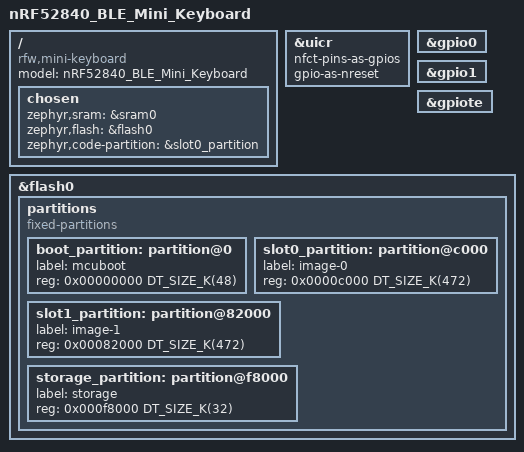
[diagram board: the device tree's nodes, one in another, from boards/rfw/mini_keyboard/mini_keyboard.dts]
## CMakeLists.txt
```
cmake_minimum_required(VERSION 3.20.0)
include_directories(inc)

find_package(Zephyr REQUIRED HINTS $ENV{ZEPHYR_BASE})

project(Keyboard)

target_sources(app PRIVATE src/main.c)
```

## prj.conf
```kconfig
CONFIG_ASSERT=y
CONFIG_HEAP_MEM_POOL_SIZE=4096

# Clock RC: Release P0.26 from XL1 crystal
CONFIG_CLOCK_CONTROL_NRF_K32SRC_RC=y
CONFIG_CLOCK_CONTROL_NRF_K32SRC_XTAL=n

# GPIO and interrupt support
CONFIG_GPIO=y

# CAF Framework & Event Manager
CONFIG_CAF=y
CONFIG_APP_EVENT_MANAGER=y
CONFIG_APP_EVENT_MANAGER_MAX_EVENT_CNT=256

# CAF Buttons module
CONFIG_CAF_BUTTONS=y
CONFIG_CAF_BUTTONS_DEF_PATH="buttons_def.h"
CONFIG_CAF_BUTTONS_POLARITY_INVERSED=n
CONFIG_CAF_BUTTONS_SCAN_INTERVAL=2
CONFIG_CAF_BUTTONS_DEBOUNCE_INTERVAL=5

# RTT Output for debugging
CONFIG_CONSOLE=y
CONFIG_USE_SEGGER_RTT=y
CONFIG_RTT_CONSOLE=y
CONFIG_LOG=y
CONFIG_LOG_BACKEND_RTT=y
```

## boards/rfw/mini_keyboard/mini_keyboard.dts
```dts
/dts-v1/;
#include <nordic/nrf52840_qiaa.dtsi>
#include "mini_keyboard-pinctrl.dtsi"

/ {
	model = "nRF52840_BLE_Mini_Keyboard";
	compatible = "rfw,mini-keyboard";

	chosen {
		zephyr,sram = &sram0;
		zephyr,flash = &flash0;
		zephyr,code-partition = &slot0_partition;
	};
};

&uicr {
	nfct-pins-as-gpios;
	gpio-as-nreset;
};

&gpio0 {
	status = "okay";
};

&gpio1 {
	status = "okay";
};

&gpiote {
	status = "okay";
};

&flash0 {
	partitions {
		compatible = "fixed-partitions";
		#address-cells = <1>;
		#size-cells = <1>;

		boot_partition: partition@0 {
			label = "mcuboot";
			reg = <0x00000000 DT_SIZE_K(48)>;
		};

		slot0_partition: partition@c000 {
			label = "image-0";
			reg = <0x0000c000 DT_SIZE_K(472)>;
		};

		slot1_partition: partition@82000 {
			label = "image-1";
			reg = <0x00082000 DT_SIZE_K(472)>;
		};

		storage_partition: partition@f8000 {
			label = "storage";
			reg = <0x000f8000 DT_SIZE_K(32)>;
		};
	};
};
```

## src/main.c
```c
/*
 * Copyright (c) 2026 rfw
 * SPDX-License-Identifier: Apache-2.0
 */

#include <zephyr/kernel.h>
#include <zephyr/sys/printk.h>
#include <app_event_manager.h>
#include <caf/events/button_event.h>
#include <caf/key_id.h>

#define MODULE main
#include <caf/events/module_state_event.h>

#include <zephyr/logging/log.h>
LOG_MODULE_REGISTER(MODULE);

static bool event_handler(const struct app_event_header *eh)
{
	if (is_button_event(eh)) {
		const struct button_event *event = cast_button_event(eh);

		if (event->pressed) {
			printk("[%d,%d]\n", KEY_ROW(event->key_id), KEY_COL(event->key_id));
		}
		return false;
	}
	return false;
}

APP_EVENT_LISTENER(main, event_handler);
APP_EVENT_SUBSCRIBE(main, button_event);

int main(void)
{
	if (app_event_manager_init()) {
		LOG_ERR("Application Event Manager init failed");
		return -1;
	}

	module_set_state(MODULE_STATE_READY);
	return 0;
}
```

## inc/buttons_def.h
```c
/*
 * Copyright (c) 2026 rfw
 * SPDX-License-Identifier: Apache-2.0
 */

#pragma once

#include <caf/gpio_pins.h>

/* 4 列驱动引脚 (全部在 Port 0) */
static const struct gpio_pin col[] = {
	{ .port = 0, .pin = 5 },   /* COL0: P0.05 */
	{ .port = 0, .pin = 6 },   /* COL1: P0.06 */
	{ .port = 0, .pin = 26 },  /* COL2: P0.26 (已释放 32.768kHz 晶振) */
	{ .port = 0, .pin = 30 },  /* COL3: P0.30 */
};

/* 6 行输入引脚 (注意 ROW4 在 Port 1) */
static const struct gpio_pin row[] = {
	{ .port = 0, .pin = 15 },  /* ROW0: P0.15 (旋钮中键按压) */
	{ .port = 0, .pin = 7 },   /* ROW1: P0.07 */
	{ .port = 0, .pin = 12 },  /* ROW2: P0.12 */
	{ .port = 0, .pin = 4 },   /* ROW3: P0.04 */
	{ .port = 1, .pin = 9 },   /* ROW4: P1.09 (Port 1 跨端口) */
	{ .port = 0, .pin = 8 },   /* ROW5: P0.08 */
};
```
